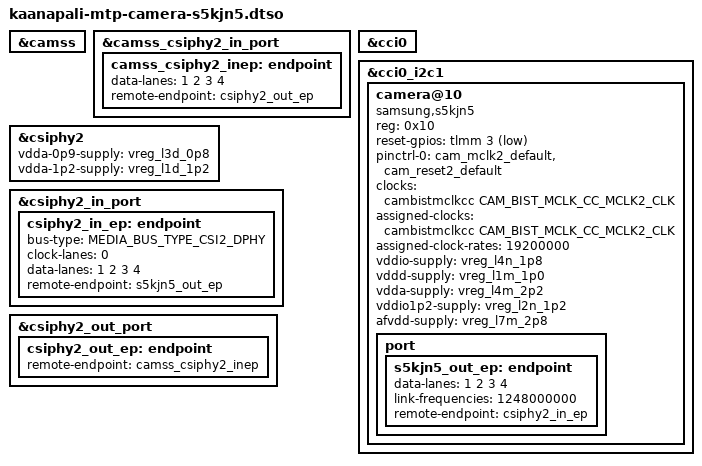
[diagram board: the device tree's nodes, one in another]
// SPDX-License-Identifier: BSD-3-Clause
/*
 * Copyright (c) Qualcomm Technologies, Inc. and/or its subsidiaries.
 */

/dts-v1/;
/plugin/;

#include <dt-bindings/clock/qcom,kaanapali-cambistmclkcc.h>
#include <dt-bindings/clock/qcom,kaanapali-camcc.h>
#include <dt-bindings/gpio/gpio.h>
#include <dt-bindings/media/video-interfaces.h>

&camss {
	status = "okay";
};

&camss_csiphy2_in_port {
	camss_csiphy2_inep: endpoint {
		data-lanes = <1 2 3 4>;
		remote-endpoint = <&csiphy2_out_ep>;
	};
};

&cci0 {
	status = "okay";
};

&cci0_i2c1 {
	#address-cells = <1>;
	#size-cells = <0>;

	camera@10 {
		compatible = "samsung,s5kjn5";
		reg = <0x10>;

		reset-gpios = <&tlmm 3 GPIO_ACTIVE_LOW>;
		pinctrl-names = "default";
		pinctrl-0 = <&cam_mclk2_default &cam_reset2_default>;

		clocks = <&cambistmclkcc CAM_BIST_MCLK_CC_MCLK2_CLK>;
		assigned-clocks = <&cambistmclkcc CAM_BIST_MCLK_CC_MCLK2_CLK>;
		assigned-clock-rates = <19200000>;

		vddio-supply = <&vreg_l4n_1p8>;
		vddd-supply = <&vreg_l1m_1p0>;
		vdda-supply = <&vreg_l4m_2p2>;
		vddio1p2-supply = <&vreg_l2n_1p2>;
		afvdd-supply = <&vreg_l7m_2p8>;

		port {
			s5kjn5_out_ep: endpoint {
				data-lanes = <1 2 3 4>;
				link-frequencies = /bits/ 64 <1248000000>;
				remote-endpoint = <&csiphy2_in_ep>;
			};
		};
	};
};

&csiphy2 {
	vdda-0p9-supply = <&vreg_l3d_0p8>;
	vdda-1p2-supply = <&vreg_l1d_1p2>;

	status = "okay";
};

&csiphy2_in_port {
	csiphy2_in_ep: endpoint {
		bus-type = <MEDIA_BUS_TYPE_CSI2_DPHY>;
		clock-lanes = <0>;
		data-lanes = <1 2 3 4>;
		remote-endpoint = <&s5kjn5_out_ep>;
	};
};

&csiphy2_out_port {
	csiphy2_out_ep: endpoint {
		remote-endpoint = <&camss_csiphy2_inep>;
	};
};
